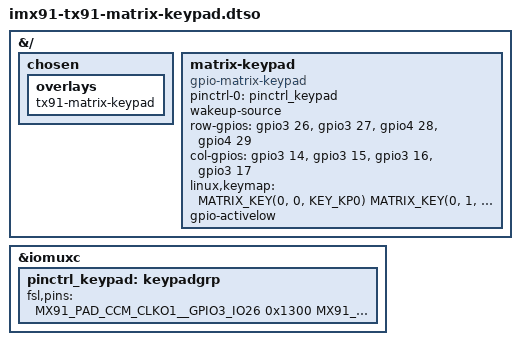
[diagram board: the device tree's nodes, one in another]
// SPDX-License-Identifier: (GPL-2.0+ OR MIT)
/*
 * Copyright 2025 Lothar Waßmann <LW@KARO-electronics.de>
 */

/dts-v1/;
/plugin/;

#include <dt-bindings/gpio/gpio.h>
#include <dt-bindings/input/input.h>
#include "imx91-pinfunc.h"

&{/} {
	chosen {
		overlays {
			tx91-matrix-keypad;
		};
	};

	matrix-keypad {
		compatible = "gpio-matrix-keypad";
		pinctrl-names = "default";
		pinctrl-0 = <&pinctrl_keypad>;
		wakeup-source;
		row-gpios = <
			     &gpio3 26 GPIO_ACTIVE_HIGH
			     &gpio3 27 GPIO_ACTIVE_HIGH
			     &gpio4 28 GPIO_ACTIVE_HIGH
			     &gpio4 29 GPIO_ACTIVE_HIGH
		>;
		col-gpios = <
			     &gpio3 14 GPIO_ACTIVE_HIGH
			     &gpio3 15 GPIO_ACTIVE_HIGH
			     &gpio3 16 GPIO_ACTIVE_HIGH
			     &gpio3 17 GPIO_ACTIVE_HIGH
		>;
		linux,keymap = <
				MATRIX_KEY(0, 0, KEY_KP0)
				MATRIX_KEY(0, 1, KEY_KP1)
				MATRIX_KEY(0, 2, KEY_KP2)
				MATRIX_KEY(0, 3, KEY_KP3)
				MATRIX_KEY(1, 0, KEY_KP4)
				MATRIX_KEY(1, 1, KEY_KP5)
				MATRIX_KEY(1, 2, KEY_KP6)
				MATRIX_KEY(1, 3, KEY_KP7)
				MATRIX_KEY(2, 0, KEY_KP8)
				MATRIX_KEY(2, 1, KEY_KP9)
				MATRIX_KEY(2, 2, KEY_ENTER)
				MATRIX_KEY(2, 3, KEY_ESC)
				MATRIX_KEY(3, 0, KEY_UP)
				MATRIX_KEY(3, 1, KEY_DOWN)
				MATRIX_KEY(3, 2, KEY_LEFT)
				MATRIX_KEY(3, 3, KEY_RIGHT)
		>;
		gpio-activelow;
	};
};

&iomuxc {
	pinctrl_keypad: keypadgrp {
		fsl,pins = <
			MX91_PAD_CCM_CLKO1__GPIO3_IO26			0x1300
			MX91_PAD_CCM_CLKO2__GPIO3_IO27			0x1300
			MX91_PAD_CCM_CLKO3__GPIO4_IO28			0x1300
			MX91_PAD_CCM_CLKO4__GPIO4_IO29			0x1300
			MX91_PAD_SD1_DATA4__GPIO3_IO14			0x31e
			MX91_PAD_SD1_DATA5__GPIO3_IO15			0x31e
			MX91_PAD_SD1_DATA6__GPIO3_IO16			0x31e
			MX91_PAD_SD1_DATA7__GPIO3_IO17			0x31e
		>;
	};
};
